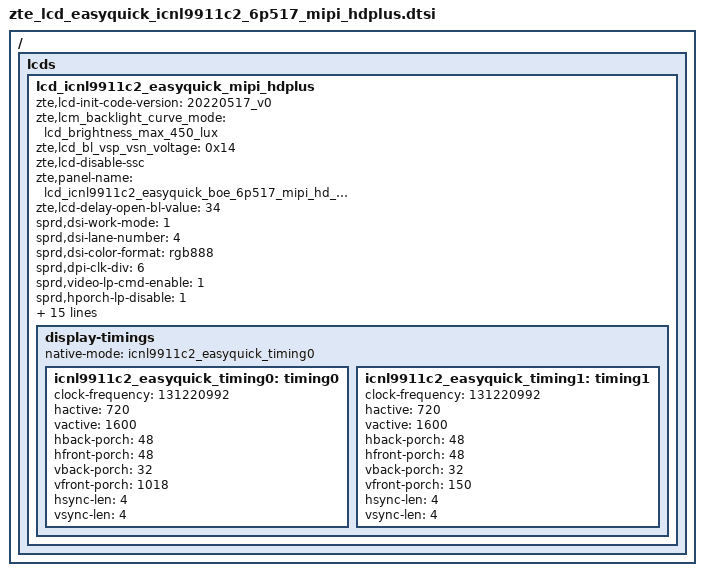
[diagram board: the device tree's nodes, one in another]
/ {
	fragment {
		target-path = "/";
		__overlay__ {
			lcds {
				lcd_icnl9911c2_easyquick_mipi_hdplus: lcd_icnl9911c2_easyquick_mipi_hdplus {
					zte,lcd-init-code-version = "20220517_v0";

					zte,lcm_backlight_curve_mode = "lcd_brightness_max_450_lux";
					zte,lcd_bl_vsp_vsn_voltage = <0x14>;
					zte,lcd-disable-ssc;
					zte,panel-name = "lcd_icnl9911c2_easyquick_boe_6p517_mipi_hd_chipone_4lane";
					zte,lcd-delay-open-bl-value = <34>;

					sprd,dsi-work-mode = <1>;
					sprd,dsi-lane-number = <4>;
					sprd,dsi-color-format = "rgb888";

					sprd,dpi-clk-div = <6>;
					sprd,video-lp-cmd-enable = <1>;
					sprd,hporch-lp-disable = <1>;

					sprd,phy-bit-clock = <787326>;
					sprd,phy-escape-clock = <20000>;/* kHz */

					sprd,width-mm = <67932>;
					sprd,height-mm = <150960>;

					/*sprd,esd-check-enable = <1>;*//* 0:close , 1:open */
					sprd,esd-check-mode = <1>;/* 0:REG ,1:TE  */
					sprd,esd-check-period = <2000>;

					sprd,reset-on-sequence = <1 5>, <0 5>, <1 30>;
					sprd,reset-off-sequence = <1 20>;

					sprd,use-dcs-write;
		sprd,initial-command = [
39 00 00 03 F0 5A 59
39 00 00 03 F1 A5 A6
39 00 00 1C B0 89 88 87 86 02 03 04 05 33 33 33 33 05 01 01 5E 01 00 0F 85 04 03 02 01 02 03 04
39 00 00 21 B1 53 42 85 81 05 01 01 5E 01 00 04 08 54 00 00 00 44 40 02 01 40 02 01 40 02 01 40 02 01 00 00 00
39 00 00 12 B2 54 C4 82 05 40 02 01 40 02 01 05 05 54 0C 0C 0D 0B
39 00 00 21 B3 02 0D 08 0E 08 26 26 91 A2 33 44 00 26 00 18 01 02 08 20 30 0E 09 42 20 00 20 40 08 09 22 33 00
39 00 00 1D B4 43 1D 23 00 04 06 1C C1 10 12 0C 0E 43 43 43 43 43 43 43 43 43 43 FF FF FC 60 00 00
39 00 00 1D B5 43 1D 23 00 05 07 1C C1 11 13 0D 0F 43 43 43 43 43 43 43 43 43 43 FF FF FC 60 00 00
39 00 00 19 B8 54 57 55 55 55 55 54 57 55 55 55 55 00 00 00 00 00 00 00 00 00 00 00 00
39 00 00 0E BB 01 05 09 11 0D 19 1D 55 25 69 00 21 25
39 00 00 0F BC 00 00 00 00 02 20 FF 00 03 33 01 73 33 00
39 00 00 0B BD E9 02 4E CF 72 A4 08 44 AE 15
39 00 00 0B BE 68 7C 46 5A 0C 77 43 07 0E 0E
39 00 00 09 BF 07 25 07 25 7F 00 11 04
39 00 00 0A C0 10 FF FF FF FF FF 00 FF 00
39 00 00 14 C1 C0 20 20 96 04 30 30 04 2A 40 36 00 07 CF FF FF 7C 01 C0
39 00 00 0A C2 CC 01 10 00 01 30 02 21 43
39 00 00 0A C3 01 00 FF 00 FF 00 00 81 01
39 00 00 0B C4 84 01 2B 41 00 3C 00 03 03 2E
39 00 00 0C C5 03 1C B8 B8 30 10 64 44 05 0A 14
39 00 00 0B C6 87 A0 2A 29 29 33 64 37 08 04
39 00 00 17 C7 FF D4 B7 9F 74 53 1F 6F 34 06 D8 A3 F7 CC AD 84 6B 49 00 7F E0 00
39 00 00 17 C8 FF D4 B7 9F 74 53 1F 6F 34 06 D8 A3 F7 CC AD 84 6B 49 00 7F E0 00
39 00 00 07 C9 43 00 1F FF 3F 03
15 00 00 02 CB 00
39 00 00 09 D0 80 0D FF 0F 61 0B 08 0C
39 00 00 0E D2 42 0C 30 01 80 26 04 00 00 C3 00 00 00
39 00 00 18 E1 EF FE FE FE FE EE F0 20 33 FF 00 00 6A 90 C0 0D 6A F0 3E FF 00 07 D0
39 00 00 1B E0 30 00 80 88 11 3F 22 62 DF A0 04 CC 01 FF F6 FF F0 FD FF FD F8 F5 FC FC FD FF
39 00 00 04 EA 46 50 00
39 00 00 04 FA 45 93 01
39 00 00 05 FE FF FF FF 50
39 00 00 03 F1 5A 59
39 00 00 03 F0 A5 A6
15 00 00 02 35 00
05 78 00 01 11
05 14 00 01 29
15 00 00 02 26 02
		];

					sprd,sleep-in-command = [
						39 01 00 02 26 08
						05 14 00 01 28
						05 78 00 01 10
						];
					sprd,sleep-out-command = [
						05 78 00 01 11
						05 64 00 01 29
						];

					display-timings {
						native-mode = <&icnl9911c2_easyquick_timing0>;
						icnl9911c2_easyquick_timing0: timing0 {/*60hz*/
							clock-frequency = <131220992>;
							hactive = <720>;
 							vactive = <1600>;
 							hback-porch = <48>;
 							hfront-porch = <48>;
 							vback-porch = <32>;
							vfront-porch = <1018>;
 							hsync-len = <4>;
 							vsync-len = <4>;
 
 						};
						 icnl9911c2_easyquick_timing1: timing1 {/*90hz*/
							clock-frequency = <131220992>;
 							hactive = <720>;
 							vactive = <1600>;
 							hback-porch = <48>;
 							hfront-porch = <48>;
 							vback-porch = <32>;
							vfront-porch = <150>;
 							hsync-len = <4>;
 							vsync-len = <4>;
 
						};
					};
					/*
					oled-backlight {
						default-brightness-level = <1632>;
						sprd,max-level = <4095>;
						brightness-levels = [
							39 00 00 03 51 00 00
							39 00 00 02 53 2C
						];
					};*/
				};
			};
		};
	};
};
